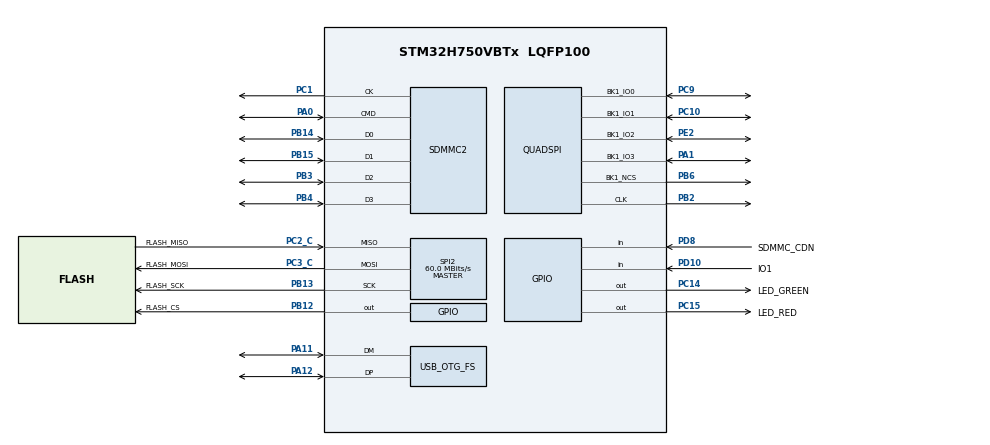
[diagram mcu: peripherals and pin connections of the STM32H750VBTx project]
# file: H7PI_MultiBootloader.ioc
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CORTEX_M7.AccessPermission-Cortex_Memory_Protection_Unit_Region0_Settings=MPU_REGION_FULL_ACCESS
CORTEX_M7.AccessPermission-Cortex_Memory_Protection_Unit_Region1_Settings=MPU_REGION_FULL_ACCESS
CORTEX_M7.AccessPermission-Cortex_Memory_Protection_Unit_Region2_Settings=MPU_REGION_FULL_ACCESS
CORTEX_M7.AccessPermission-Cortex_Memory_Protection_Unit_Region3_Settings=MPU_REGION_FULL_ACCESS
CORTEX_M7.AccessPermission-Cortex_Memory_Protection_Unit_Region4_Settings=MPU_REGION_FULL_ACCESS
CORTEX_M7.BaseAddress-Cortex_Memory_Protection_Unit_Region0_Settings=0x60000000
CORTEX_M7.BaseAddress-Cortex_Memory_Protection_Unit_Region1_Settings=0x24000000
CORTEX_M7.BaseAddress-Cortex_Memory_Protection_Unit_Region2_Settings=0x30000000
CORTEX_M7.BaseAddress-Cortex_Memory_Protection_Unit_Region3_Settings=0x38000000
CORTEX_M7.BaseAddress-Cortex_Memory_Protection_Unit_Region4_Settings=0x20000000
CORTEX_M7.CPU_DCache=Enabled
CORTEX_M7.CPU_ICache=Enabled
CORTEX_M7.Enable-Cortex_Memory_Protection_Unit_Region0_Settings=MPU_REGION_ENABLE
CORTEX_M7.Enable-Cortex_Memory_Protection_Unit_Region1_Settings=MPU_REGION_ENABLE
CORTEX_M7.Enable-Cortex_Memory_Protection_Unit_Region2_Settings=MPU_REGION_ENABLE
CORTEX_M7.Enable-Cortex_Memory_Protection_Unit_Region3_Settings=MPU_REGION_ENABLE
CORTEX_M7.Enable-Cortex_Memory_Protection_Unit_Region4_Settings=MPU_REGION_ENABLE
CORTEX_M7.IsBufferable-Cortex_Memory_Protection_Unit_Region0_Settings=MPU_ACCESS_BUFFERABLE
CORTEX_M7.IsBufferable-Cortex_Memory_Protection_Unit_Region1_Settings=MPU_ACCESS_BUFFERABLE
CORTEX_M7.IsBufferable-Cortex_Memory_Protection_Unit_Region2_Settings=MPU_ACCESS_BUFFERABLE
CORTEX_M7.IsBufferable-Cortex_Memory_Protection_Unit_Region3_Settings=MPU_ACCESS_BUFFERABLE
CORTEX_M7.IsBufferable-Cortex_Memory_Protection_Unit_Region4_Settings=MPU_ACCESS_BUFFERABLE
CORTEX_M7.IsCacheable-Cortex_Memory_Protection_Unit_Region1_Settings=MPU_ACCESS_CACHEABLE
CORTEX_M7.IsCacheable-Cortex_Memory_Protection_Unit_Region2_Settings=MPU_ACCESS_CACHEABLE
CORTEX_M7.IsCacheable-Cortex_Memory_Protection_Unit_Region3_Settings=MPU_ACCESS_CACHEABLE
CORTEX_M7.IsCacheable-Cortex_Memory_Protection_Unit_Region4_Settings=MPU_ACCESS_CACHEABLE
CORTEX_M7.IsShareable-Cortex_Memory_Protection_Unit_Region0_Settings=MPU_ACCESS_SHAREABLE
CORTEX_M7.IsShareable-Cortex_Memory_Protection_Unit_Region1_Settings=MPU_ACCESS_SHAREABLE
CORTEX_M7.IsShareable-Cortex_Memory_Protection_Unit_Region2_Settings=MPU_ACCESS_SHAREABLE
CORTEX_M7.IsShareable-Cortex_Memory_Protection_Unit_Region3_Settings=MPU_ACCESS_SHAREABLE
CORTEX_M7.IsShareable-Cortex_Memory_Protection_Unit_Region4_Settings=MPU_ACCESS_SHAREABLE
CORTEX_M7.MPU_Control=MPU_HFNMI_PRIVDEF
CORTEX_M7.Size-Cortex_Memory_Protection_Unit_Region0_Settings=MPU_REGION_SIZE_256KB
CORTEX_M7.Size-Cortex_Memory_Protection_Unit_Region1_Settings=MPU_REGION_SIZE_512KB
CORTEX_M7.Size-Cortex_Memory_Protection_Unit_Region2_Settings=MPU_REGION_SIZE_512KB
CORTEX_M7.Size-Cortex_Memory_Protection_Unit_Region3_Settings=MPU_REGION_SIZE_64KB
CORTEX_M7.Size-Cortex_Memory_Protection_Unit_Region4_Settings=MPU_REGION_SIZE_128KB
CORTEX_M7.TypeExtField-Cortex_Memory_Protection_Unit_Region1_Settings=MPU_TEX_LEVEL1
CORTEX_M7.TypeExtField-Cortex_Memory_Protection_Unit_Region2_Settings=MPU_TEX_LEVEL1
CORTEX_M7.TypeExtField-Cortex_Memory_Protection_Unit_Region3_Settings=MPU_TEX_LEVEL1
CORTEX_M7.TypeExtField-Cortex_Memory_Protection_Unit_Region4_Settings=MPU_TEX_LEVEL1
Dma.MEMTOMEM.0.Direction=DMA_MEMORY_TO_MEMORY
Dma.MEMTOMEM.0.EventEnable=DISABLE
Dma.MEMTOMEM.0.FIFOMode=DMA_FIFOMODE_ENABLE
Dma.MEMTOMEM.0.FIFOThreshold=DMA_FIFO_THRESHOLD_FULL
Dma.MEMTOMEM.0.Instance=DMA1_Stream0
Dma.MEMTOMEM.0.MemBurst=DMA_MBURST_SINGLE
Dma.MEMTOMEM.0.MemDataAlignment=DMA_MDATAALIGN_BYTE
Dma.MEMTOMEM.0.MemInc=DMA_MINC_ENABLE
Dma.MEMTOMEM.0.Mode=DMA_NORMAL
Dma.MEMTOMEM.0.PeriphBurst=DMA_PBURST_SINGLE
Dma.MEMTOMEM.0.PeriphDataAlignment=DMA_PDATAALIGN_BYTE
Dma.MEMTOMEM.0.PeriphInc=DMA_PINC_ENABLE
Dma.MEMTOMEM.0.Polarity=HAL_DMAMUX_REQ_GEN_RISING
Dma.MEMTOMEM.0.Priority=DMA_PRIORITY_LOW
Dma.MEMTOMEM.0.RequestNumber=1
Dma.MEMTOMEM.0.SignalID=NONE
Dma.MEMTOMEM.0.SyncEnable=DISABLE
Dma.MEMTOMEM.0.SyncPolarity=HAL_DMAMUX_SYNC_NO_EVENT
Dma.MEMTOMEM.0.SyncRequestNumber=1
Dma.MEMTOMEM.0.SyncSignalID=NONE
Dma.Request0=MEMTOMEM
Mcu.Family=STM32H7
Mcu.Name=STM32H750VBTx
Mcu.Package=LQFP100
NVIC.OTG_FS_IRQn=true\:0\:0\:false\:false\:true\:true\:true
NVIC.PriorityGroup=NVIC_PRIORITYGROUP_4
NVIC.QUADSPI_IRQn=true\:0\:0\:false\:false\:true\:true\:true
NVIC.SDMMC2_IRQn=true\:0\:0\:false\:false\:true\:true\:true
NVIC.SPI2_IRQn=true\:0\:0\:false\:false\:true\:true\:true
PA0.GPIO_PuPd=GPIO_PULLUP
PA0.Mode=SD_4_bits_Wide_bus
PA0.Signal=SDMMC2_CMD
PA1.GPIO_PuPd=GPIO_PULLUP
PA1.GPIO_Speed=GPIO_SPEED_FREQ_VERY_HIGH
PA1.Mode=Single Bank 1
PA1.Signal=QUADSPI_BK1_IO3
PA11.GPIO_Speed=GPIO_SPEED_FREQ_VERY_HIGH
PA11.Mode=Device_Only
PA11.Signal=USB_OTG_FS_DM
PA12.GPIO_Speed=GPIO_SPEED_FREQ_VERY_HIGH
PA12.Mode=Device_Only
PA12.Signal=USB_OTG_FS_DP
PA13\ (JTMS/SWDIO).Signal=DEBUG_JTMS-SWDIO
PA14\ (JTCK/SWCLK).Signal=DEBUG_JTCK-SWCLK
PB12.GPIO_Label=FLASH_CS
PB12.GPIO_PuPd=GPIO_PULLUP
PB12.GPIO_Speed=GPIO_SPEED_FREQ_VERY_HIGH
PB12.Signal=GPIO_Output
PB13.GPIO_Label=FLASH_SCK
PB13.GPIO_Speed=GPIO_SPEED_FREQ_VERY_HIGH
PB13.Mode=Full_Duplex_Master
PB13.Signal=SPI2_SCK
PB14.GPIO_PuPd=GPIO_PULLUP
PB14.Mode=SD_4_bits_Wide_bus
PB14.Signal=SDMMC2_D0
PB15.GPIO_PuPd=GPIO_PULLUP
PB15.Mode=SD_4_bits_Wide_bus
PB15.Signal=SDMMC2_D1
PB2.GPIO_PuPd=GPIO_PULLUP
PB2.GPIO_Speed=GPIO_SPEED_FREQ_VERY_HIGH
PB2.Mode=Single Bank 1
PB2.Signal=QUADSPI_CLK
PB3\ (JTDO/TRACESWO).GPIO_PuPd=GPIO_PULLUP
PB3\ (JTDO/TRACESWO).Mode=SD_4_bits_Wide_bus
PB3\ (JTDO/TRACESWO).Signal=SDMMC2_D2
PB4\ (NJTRST).GPIO_PuPd=GPIO_PULLUP
PB4\ (NJTRST).Mode=SD_4_bits_Wide_bus
PB4\ (NJTRST).Signal=SDMMC2_D3
PB6.GPIO_FM6=__NULL
PB6.GPIO_PuPd=GPIO_PULLUP
PB6.GPIO_Speed=GPIO_SPEED_FREQ_VERY_HIGH
PB6.Mode=Single Bank 1
PB6.Signal=QUADSPI_BK1_NCS
PC1.GPIO_PuPd=GPIO_PULLUP
PC1.Mode=SD_4_bits_Wide_bus
PC1.Signal=SDMMC2_CK
PC10.GPIO_PuPd=GPIO_PULLUP
PC10.GPIO_Speed=GPIO_SPEED_FREQ_VERY_HIGH
PC10.Mode=Single Bank 1
PC10.Signal=QUADSPI_BK1_IO1
PC14-OSC32_IN\ (OSC32_IN).GPIO_Label=LED_GREEN
PC14-OSC32_IN\ (OSC32_IN).Signal=GPIO_Output
PC15-OSC32_OUT\ (OSC32_OUT).GPIO_Label=LED_RED
PC15-OSC32_OUT\ (OSC32_OUT).Signal=GPIO_Output
PC2_C.GPIO_Label=FLASH_MISO
PC2_C.GPIO_Speed=GPIO_SPEED_FREQ_VERY_HIGH
PC2_C.Mode=Full_Duplex_Master
PC2_C.Signal=SPI2_MISO
PC3_C.GPIO_Label=FLASH_MOSI
PC3_C.GPIO_Speed=GPIO_SPEED_FREQ_VERY_HIGH
PC3_C.Mode=Full_Duplex_Master
PC3_C.Signal=SPI2_MOSI
PC9.GPIO_PuPd=GPIO_PULLUP
PC9.GPIO_Speed=GPIO_SPEED_FREQ_VERY_HIGH
PC9.Mode=Single Bank 1
PC9.Signal=QUADSPI_BK1_IO0
PD10.GPIO_Label=IO1
PD10.GPIO_PuPd=GPIO_PULLDOWN
PD10.Signal=GPIO_Input
PD8.GPIO_Label=SDMMC_CDN
PD8.Signal=GPIO_Input
PE2.GPIO_PuPd=GPIO_PULLUP
PE2.GPIO_Speed=GPIO_SPEED_FREQ_VERY_HIGH
PE2.Mode=Single Bank 1
PE2.Signal=QUADSPI_BK1_IO2
ProjectManager.HeapSize=0x10000
ProjectManager.StackSize=0x10000
ProjectManager.TargetToolchain=Makefile
QUADSPI.ChipSelectHighTime=QSPI_CS_HIGH_TIME_8_CYCLE
QUADSPI.ClockMode=QSPI_CLOCK_MODE_0
QUADSPI.ClockPrescaler=2
QUADSPI.FifoThreshold=32
QUADSPI.FlashSize=22
QUADSPI.SampleShifting=QSPI_SAMPLE_SHIFTING_HALFCYCLE
RCC.ADCFreq_Value=240000000
RCC.APB1Freq_Value=120000000
RCC.APB2Freq_Value=120000000
RCC.APB3Freq_Value=120000000
RCC.APB4Freq_Value=120000000
RCC.CortexFreq_Value=480000000
RCC.D1PPRE=RCC_APB3_DIV2
RCC.D2PPRE1=RCC_APB1_DIV2
RCC.D2PPRE2=RCC_APB2_DIV2
RCC.D3PPRE=RCC_APB4_DIV2
RCC.DIVM1=4
RCC.DIVM2=4
RCC.DIVM3=4
RCC.DIVN1=60
RCC.DIVN2=15
RCC.DIVN3=15
RCC.DIVP2=1
RCC.DIVP3=1
RCC.DIVQ1=4
RCC.DIVQ2=8
RCC.DIVQ3=8
RCC.DIVR2=1
RCC.DIVR3=8
RCC.FMCCLockSelection=RCC_FMCCLKSOURCE_PLL
RCC.HCLKFreq_Value=240000000
RCC.HPRE=RCC_HCLK_DIV2
RCC.HSE_VALUE=24000000
RCC.PLL2FRACN=0
RCC.PLL3FRACN=0
RCC.PLLFRACN=0
RCC.SYSCLKFreq_VALUE=480000000
RCC.SYSCLKSource=RCC_SYSCLKSOURCE_PLLCLK
RCC.USBCLockSelection=RCC_USBCLKSOURCE_HSI48
RCC.USBFreq_Value=48000000
SDMMC2.ClockDiv=2
SDMMC2.HardwareFlowControl=SDMMC_HARDWARE_FLOW_CONTROL_DISABLE
SDMMC2.USE_SD_TRANSCEIVER=1U
SPI2.BaudRatePrescaler=SPI_BAUDRATEPRESCALER_4
SPI2.CLKPhase=SPI_PHASE_2EDGE
SPI2.CLKPolarity=SPI_POLARITY_HIGH
SPI2.CRCCalculation=SPI_CRCCALCULATION_ENABLE
SPI2.CalculateBaudRate=60.0 MBits/s
SPI2.DataSize=SPI_DATASIZE_8BIT
SPI2.Direction=SPI_DIRECTION_2LINES
SPI2.FifoThreshold=SPI_FIFO_THRESHOLD_01DATA
SPI2.MasterKeepIOState=SPI_MASTER_KEEP_IO_STATE_ENABLE
SPI2.Mode=SPI_MODE_MASTER
SPI2.NSSPMode=SPI_NSS_PULSE_ENABLE
SPI2.VirtualType=VM_MASTER
USB_OTG_FS.VirtualMode=Device_Only
board=custom

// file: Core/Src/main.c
/* USER CODE BEGIN Header */
/**
  ******************************************************************************
  * @file           : main.c
  * @brief          : Main program body
  ******************************************************************************
  * @attention
  *
  * <h2><center>&copy; Copyright (c) 2019 STMicroelectronics.
  * All rights reserved.</center></h2>
  *
  * This software component is licensed by ST under Ultimate Liberty license
  * SLA0044, the "License"; You may not use this file except in compliance with
  * the License. You may obtain a copy of the License at:
  *                             www.st.com/SLA0044
  *
  ******************************************************************************
  */
/* USER CODE END Header */

#include "main.h"
#include "dma.h"
#include "quadspi.h"
#include "sdmmc.h"
#include "spi.h"
#include "usb_otg.h"
#include "gpio.h"

void SystemClock_Config(void);
static void MPU_Config(void);
/* USER CODE BEGIN PFP */
void StartDefaultTask(void const * argument);
/* USER CODE END PFP */

int main(void)
{

  /* MPU Configuration--------------------------------------------------------*/
  MPU_Config();

  /* Enable I-Cache---------------------------------------------------------*/
  SCB_EnableICache();

  /* Enable D-Cache---------------------------------------------------------*/
  SCB_EnableDCache();

  /* MCU Configuration--------------------------------------------------------*/

  /* Reset of all peripherals, Initializes the Flash interface and the Systick. */
  HAL_Init();

  /* Configure the system clock */
  SystemClock_Config();

  /* Initialize all configured peripherals */
  MX_GPIO_Init();
  MX_DMA_Init();
  MX_QUADSPI_Init();
  MX_SPI2_Init();
  MX_SDMMC2_SD_Init();
  MX_USB_OTG_FS_PCD_Init();
  /* USER CODE BEGIN 2 */
	StartDefaultTask(0);
  /* USER CODE END 2 */

  /* Infinite loop */
  while (1)
  {

  }
}

void SystemClock_Config(void)
{
  RCC_OscInitTypeDef RCC_OscInitStruct = {0};
  RCC_ClkInitTypeDef RCC_ClkInitStruct = {0};
  RCC_PeriphCLKInitTypeDef PeriphClkInitStruct = {0};

  /** Supply configuration update enable
  */
  HAL_PWREx_ConfigSupply(PWR_LDO_SUPPLY);
  /** Configure the main internal regulator output voltage
  */
  __HAL_PWR_VOLTAGESCALING_CONFIG(PWR_REGULATOR_VOLTAGE_SCALE0);

  while(!__HAL_PWR_GET_FLAG(PWR_FLAG_VOSRDY)) {}
  /** Initializes the CPU, AHB and APB busses clocks
  */
  RCC_OscInitStruct.OscillatorType = RCC_OSCILLATORTYPE_HSI48|RCC_OSCILLATORTYPE_HSI;
  RCC_OscInitStruct.HSIState = RCC_HSI_DIV1;
  RCC_OscInitStruct.HSICalibrationValue = RCC_HSICALIBRATION_DEFAULT;
  RCC_OscInitStruct.HSI48State = RCC_HSI48_ON;
  RCC_OscInitStruct.PLL.PLLState = RCC_PLL_ON;
  RCC_OscInitStruct.PLL.PLLSource = RCC_PLLSOURCE_HSI;
  RCC_OscInitStruct.PLL.PLLM = 4;
  RCC_OscInitStruct.PLL.PLLN = 60;
  RCC_OscInitStruct.PLL.PLLP = 2;
  RCC_OscInitStruct.PLL.PLLQ = 4;
  RCC_OscInitStruct.PLL.PLLR = 2;
  RCC_OscInitStruct.PLL.PLLRGE = RCC_PLL1VCIRANGE_3;
  RCC_OscInitStruct.PLL.PLLVCOSEL = RCC_PLL1VCOWIDE;
  RCC_OscInitStruct.PLL.PLLFRACN = 0;
  if (HAL_RCC_OscConfig(&RCC_OscInitStruct) != HAL_OK)
  {
    Error_Handler();
  }
  /** Initializes the CPU, AHB and APB busses clocks
  */
  RCC_ClkInitStruct.ClockType = RCC_CLOCKTYPE_HCLK|RCC_CLOCKTYPE_SYSCLK
                              |RCC_CLOCKTYPE_PCLK1|RCC_CLOCKTYPE_PCLK2
                              |RCC_CLOCKTYPE_D3PCLK1|RCC_CLOCKTYPE_D1PCLK1;
  RCC_ClkInitStruct.SYSCLKSource = RCC_SYSCLKSOURCE_PLLCLK;
  RCC_ClkInitStruct.SYSCLKDivider = RCC_SYSCLK_DIV1;
  RCC_ClkInitStruct.AHBCLKDivider = RCC_HCLK_DIV2;
  RCC_ClkInitStruct.APB3CLKDivider = RCC_APB3_DIV2;
  RCC_ClkInitStruct.APB1CLKDivider = RCC_APB1_DIV2;
  RCC_ClkInitStruct.APB2CLKDivider = RCC_APB2_DIV2;
  RCC_ClkInitStruct.APB4CLKDivider = RCC_APB4_DIV2;

  if (HAL_RCC_ClockConfig(&RCC_ClkInitStruct, FLASH_LATENCY_4) != HAL_OK)
  {
    Error_Handler();
  }
  PeriphClkInitStruct.PeriphClockSelection = RCC_PERIPHCLK_SPI2|RCC_PERIPHCLK_SDMMC
                              |RCC_PERIPHCLK_USB|RCC_PERIPHCLK_QSPI;
  PeriphClkInitStruct.QspiClockSelection = RCC_QSPICLKSOURCE_D1HCLK;
  PeriphClkInitStruct.SdmmcClockSelection = RCC_SDMMCCLKSOURCE_PLL;
  PeriphClkInitStruct.Spi123ClockSelection = RCC_SPI123CLKSOURCE_PLL;
  PeriphClkInitStruct.UsbClockSelection = RCC_USBCLKSOURCE_HSI48;
  if (HAL_RCCEx_PeriphCLKConfig(&PeriphClkInitStruct) != HAL_OK)
  {
    Error_Handler();
  }
  /** Enable USB Voltage detector
  */
  HAL_PWREx_EnableUSBVoltageDetector();
}

/* MPU Configuration */

void MPU_Config(void)
{
  MPU_Region_InitTypeDef MPU_InitStruct = {0};

  /* Disables the MPU */
  HAL_MPU_Disable();
  /** Initializes and configures the Region and the memory to be protected
  */
  MPU_InitStruct.Enable = MPU_REGION_ENABLE;
  MPU_InitStruct.Number = MPU_REGION_NUMBER0;
  MPU_InitStruct.BaseAddress = 0x60000000;
  MPU_InitStruct.Size = MPU_REGION_SIZE_256KB;
  MPU_InitStruct.SubRegionDisable = 0x0;
  MPU_InitStruct.TypeExtField = MPU_TEX_LEVEL0;
  MPU_InitStruct.AccessPermission = MPU_REGION_FULL_ACCESS;
  MPU_InitStruct.DisableExec = MPU_INSTRUCTION_ACCESS_ENABLE;
  MPU_InitStruct.IsShareable = MPU_ACCESS_SHAREABLE;
  MPU_InitStruct.IsCacheable = MPU_ACCESS_NOT_CACHEABLE;
  MPU_InitStruct.IsBufferable = MPU_ACCESS_BUFFERABLE;

  HAL_MPU_ConfigRegion(&MPU_InitStruct);
  /** Initializes and configures the Region and the memory to be protected
  */
  MPU_InitStruct.Enable = MPU_REGION_ENABLE;
  MPU_InitStruct.Number = MPU_REGION_NUMBER1;
  MPU_InitStruct.BaseAddress = 0x24000000;
  MPU_InitStruct.Size = MPU_REGION_SIZE_512KB;
  MPU_InitStruct.SubRegionDisable = 0x0;
  MPU_InitStruct.TypeExtField = MPU_TEX_LEVEL1;
  MPU_InitStruct.AccessPermission = MPU_REGION_FULL_ACCESS;
  MPU_InitStruct.DisableExec = MPU_INSTRUCTION_ACCESS_ENABLE;
  MPU_InitStruct.IsShareable = MPU_ACCESS_SHAREABLE;
  MPU_InitStruct.IsCacheable = MPU_ACCESS_CACHEABLE;
  MPU_InitStruct.IsBufferable = MPU_ACCESS_BUFFERABLE;

  HAL_MPU_ConfigRegion(&MPU_InitStruct);
  /** Initializes and configures the Region and the memory to be protected
  */
  MPU_InitStruct.Enable = MPU_REGION_ENABLE;
  MPU_InitStruct.Number = MPU_REGION_NUMBER2;
  MPU_InitStruct.BaseAddress = 0x30000000;
  MPU_InitStruct.Size = MPU_REGION_SIZE_512KB;
  MPU_InitStruct.SubRegionDisable = 0x0;
  MPU_InitStruct.TypeExtField = MPU_TEX_LEVEL1;
  MPU_InitStruct.AccessPermission = MPU_REGION_FULL_ACCESS;
  MPU_InitStruct.DisableExec = MPU_INSTRUCTION_ACCESS_ENABLE;
  MPU_InitStruct.IsShareable = MPU_ACCESS_SHAREABLE;
  MPU_InitStruct.IsCacheable = MPU_ACCESS_CACHEABLE;
  MPU_InitStruct.IsBufferable = MPU_ACCESS_BUFFERABLE;

  HAL_MPU_ConfigRegion(&MPU_InitStruct);
  /** Initializes and configures the Region and the memory to be protected
  */
  MPU_InitStruct.Enable = MPU_REGION_ENABLE;
  MPU_InitStruct.Number = MPU_REGION_NUMBER3;
  MPU_InitStruct.BaseAddress = 0x38000000;
  MPU_InitStruct.Size = MPU_REGION_SIZE_64KB;
  MPU_InitStruct.SubRegionDisable = 0x0;
  MPU_InitStruct.TypeExtField = MPU_TEX_LEVEL1;
  MPU_InitStruct.AccessPermission = MPU_REGION_FULL_ACCESS;
  MPU_InitStruct.DisableExec = MPU_INSTRUCTION_ACCESS_ENABLE;
  MPU_InitStruct.IsShareable = MPU_ACCESS_SHAREABLE;
  MPU_InitStruct.IsCacheable = MPU_ACCESS_CACHEABLE;
  MPU_InitStruct.IsBufferable = MPU_ACCESS_BUFFERABLE;

  HAL_MPU_ConfigRegion(&MPU_InitStruct);
  /** Initializes and configures the Region and the memory to be protected
  */
  MPU_InitStruct.Enable = MPU_REGION_ENABLE;
  MPU_InitStruct.Number = MPU_REGION_NUMBER4;
  MPU_InitStruct.BaseAddress = 0x20000000;
  MPU_InitStruct.Size = MPU_REGION_SIZE_128KB;
  MPU_InitStruct.SubRegionDisable = 0x0;
  MPU_InitStruct.TypeExtField = MPU_TEX_LEVEL1;
  MPU_InitStruct.AccessPermission = MPU_REGION_FULL_ACCESS;
  MPU_InitStruct.DisableExec = MPU_INSTRUCTION_ACCESS_ENABLE;
  MPU_InitStruct.IsShareable = MPU_ACCESS_SHAREABLE;
  MPU_InitStruct.IsCacheable = MPU_ACCESS_CACHEABLE;
  MPU_InitStruct.IsBufferable = MPU_ACCESS_BUFFERABLE;

  HAL_MPU_ConfigRegion(&MPU_InitStruct);
  /* Enables the MPU */
  HAL_MPU_Enable(MPU_HFNMI_PRIVDEF);

}

void Error_Handler(void)
{
}

/************************ (C) COPYRIGHT STMicroelectronics *****END OF FILE****/
